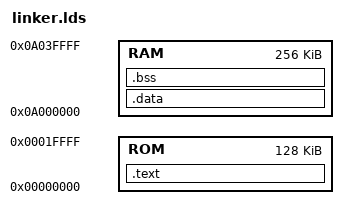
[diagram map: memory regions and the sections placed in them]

ENTRY(_start)

MEMORY
{
        ROM : ORIGIN = 0x00000000, LENGTH = 128k
        /* RAM : ORIGIN = 0x0FFFE000 LENGTH = 8k */ /* internal RAM */
        RAM : ORIGIN = 0x0A000000, LENGTH = 256k /* external RAM */
}

SECTIONS
{
        /**********************************************************************
         *                                                                    *
         **********************************************************************/
        _text_start = .;
        .text : AT(_text_start)
        {
                _stext = .;
                KEEP(*(.vectors))
                *(.startup)
                *(.text)
                *(.text.*)
                *(.rodata)
                *(.rodata.*)
                *(.eh_frame)
                . = ALIGN(0x10);
                _etext = .;
        } > ROM
        /**********************************************************************
         *                                                                    *
         **********************************************************************/
        _data_start = _text_start + SIZEOF(.text);
        .data : AT(_data_start)
        {
                _sdata = .;
                *(.data)
                *(.data.*)
                *(.sdata)
                *(.sdata.*)
                _sdata2 = .;
                *(.sdata2)
                . = ALIGN(0x10);
                _edata = .;
        } > RAM
        /**********************************************************************
         *                                                                    *
         **********************************************************************/
        .bss ADDR(.data) + SIZEOF(.data) (NOLOAD) :
        {
                _sbss = .;
                *(.bss)
                *(.bss.*)
                *(.sbss)
                *(.sbss.*)
                *(.dynbss)
                *(.scommon)
                *(COMMON)
                . = ALIGN(0x10);
                _ebss = .;
        } > RAM
        /**********************************************************************
         *                                                                    *
         **********************************************************************/
        .debug_info     0 : { *(.debug_info) }
        .debug_abbrev   0 : { *(.debug_abbrev) }
        .debug_aranges  0 : { *(.debug_aranges) }
        .debug_frame    0 : { *(.debug_frame) }
        .debug_line     0 : { *(.debug_line) }
        .debug_line_str 0 : { *(.debug_line_str) }
        .debug_loclists 0 : { *(.debug_loclists) }
        .debug_macro    0 : { *(.debug_macro) }
        .debug_names    0 : { *(.debug_names) }
        .debug_rnglists 0 : { *(.debug_rnglists) }
        .debug_str      0 : { *(.debug_str) }
        /**********************************************************************
         *                                                                    *
         **********************************************************************/
        /DISCARD/ :
        {
                *(*)
        }
}

